AUTOSAR XML (schema 00044)
package /ComponentTypes
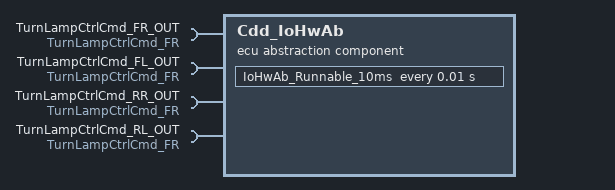
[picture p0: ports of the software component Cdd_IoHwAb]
  ecu abstraction sw component type Cdd_IoHwAb
    4 x require port, all with nonqueued-receiver-com-spec=data-element=u8_signa, required-interface=TurnLampCtrlCmd_FR:
      TurnLampCtrlCmd_FR_OUT
      TurnLampCtrlCmd_FL_OUT
      TurnLampCtrlCmd_RR_OUT
      TurnLampCtrlCmd_RL_OUT
    behavior Cdd_IoHwAb_InternalBehavior
      timing event TMT_IoHwAb_Runnable_10ms: start-on-event=IoHwAb_Runnable_10ms, period=0.01
      runnable IoHwAb_Runnable_10ms: minimum-start-interval=0.01
        data-receive-point-by-arguments:
          4 x access:
            REC_TurnLampCtrlCmd_FL_OUT_u8_signa: accessed-variable=TurnLampCtrlCmd_FL_OUT.u8_signa
            REC_TurnLampCtrlCmd_FR_OUT_u8_signa: accessed-variable=TurnLampCtrlCmd_FR_OUT.u8_signa
            REC_TurnLampCtrlCmd_RL_OUT_u8_signa: accessed-variable=TurnLampCtrlCmd_RL_OUT.u8_signa
            REC_TurnLampCtrlCmd_RR_OUT_u8_signa: accessed-variable=TurnLampCtrlCmd_RR_OUT.u8_signa
  swc implementation Cdd_IoHwAb_Implementation: behavior=Cdd_IoHwAb_InternalBehavior
